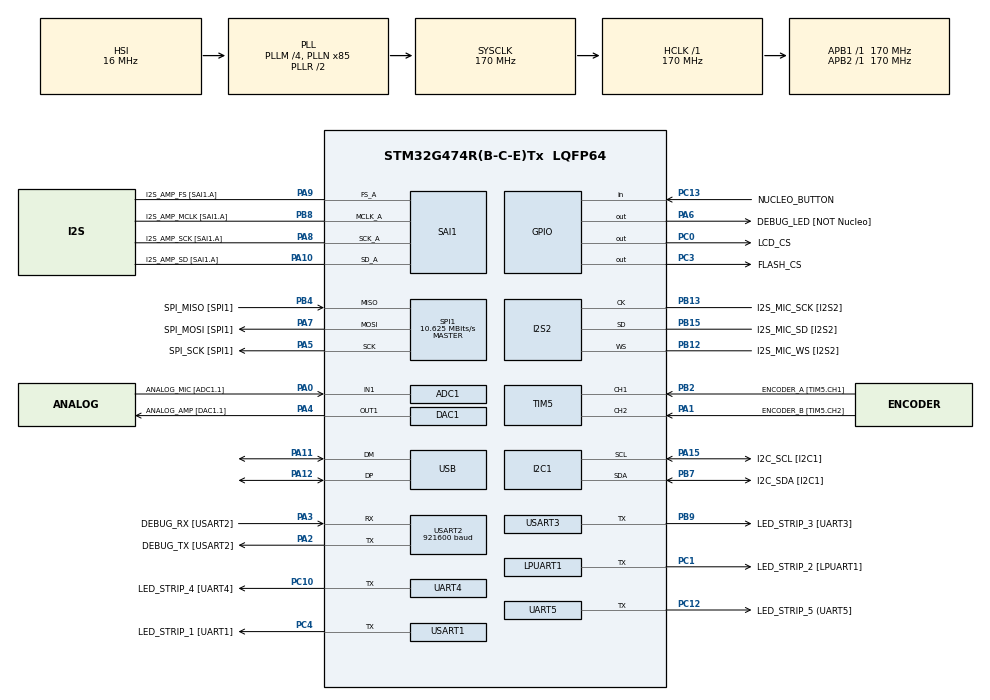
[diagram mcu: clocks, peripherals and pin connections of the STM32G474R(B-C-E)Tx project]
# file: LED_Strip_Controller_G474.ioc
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ADC1.Channel-0\#ChannelRegularConversion=ADC_CHANNEL_1
ADC1.NbrOfConversionFlag=1
ADC1.OffsetNumber-0\#ChannelRegularConversion=ADC_OFFSET_NONE
ADC1.Rank-0\#ChannelRegularConversion=1
ADC1.SamplingTime-0\#ChannelRegularConversion=ADC_SAMPLETIME_2CYCLES_5
ADC1.master=1
CRC.DefaultInitValueUse=DEFAULT_INIT_VALUE_DISABLE
CRC.DefaultPolynomialUse=DEFAULT_POLYNOMIAL_ENABLE
CRC.InitValue=0xFFFFFFFF
CRC.InputDataInversionMode=CRC_INPUTDATA_INVERSION_BYTE
CRC.OutputDataInversionMode=CRC_OUTPUTDATA_INVERSION_ENABLE
DAC1.DAC_Channel-DAC_OUT2_Int=DAC_CHANNEL_2
DAC3.DAC_Channel-DAC_OUT2_Int=DAC_CHANNEL_2
DAC4.DAC_Channel-DAC_OUT2_Int=DAC_CHANNEL_2
Dma.LPUART1_TX.2.Direction=DMA_MEMORY_TO_PERIPH
Dma.LPUART1_TX.2.EventEnable=DISABLE
Dma.LPUART1_TX.2.Instance=DMA1_Channel2
Dma.LPUART1_TX.2.MemDataAlignment=DMA_MDATAALIGN_BYTE
Dma.LPUART1_TX.2.MemInc=DMA_MINC_ENABLE
Dma.LPUART1_TX.2.Mode=DMA_NORMAL
Dma.LPUART1_TX.2.PeriphDataAlignment=DMA_PDATAALIGN_BYTE
Dma.LPUART1_TX.2.PeriphInc=DMA_PINC_DISABLE
Dma.LPUART1_TX.2.Polarity=HAL_DMAMUX_REQ_GEN_RISING
Dma.LPUART1_TX.2.Priority=DMA_PRIORITY_LOW
Dma.LPUART1_TX.2.RequestNumber=1
Dma.LPUART1_TX.2.SignalID=NONE
Dma.LPUART1_TX.2.SyncEnable=DISABLE
Dma.LPUART1_TX.2.SyncPolarity=HAL_DMAMUX_SYNC_NO_EVENT
Dma.LPUART1_TX.2.SyncRequestNumber=1
Dma.LPUART1_TX.2.SyncSignalID=NONE
Dma.Request0=USART1_TX
Dma.Request1=USART3_TX
Dma.Request2=LPUART1_TX
Dma.Request3=SPI1_TX
Dma.Request4=UART4_TX
Dma.Request5=UART5_TX
Dma.Request6=SPI2_RX
Dma.Request7=SAI1_A
Dma.Request8=SPI1_RX
Dma.SAI1_A.7.Direction=DMA_MEMORY_TO_PERIPH
Dma.SAI1_A.7.EventEnable=DISABLE
Dma.SAI1_A.7.Instance=DMA1_Channel7
Dma.SAI1_A.7.MemDataAlignment=DMA_MDATAALIGN_WORD
Dma.SAI1_A.7.MemInc=DMA_MINC_ENABLE
Dma.SAI1_A.7.Mode=DMA_CIRCULAR
Dma.SAI1_A.7.PeriphDataAlignment=DMA_PDATAALIGN_WORD
Dma.SAI1_A.7.PeriphInc=DMA_PINC_DISABLE
Dma.SAI1_A.7.Polarity=HAL_DMAMUX_REQ_GEN_RISING
Dma.SAI1_A.7.Priority=DMA_PRIORITY_LOW
Dma.SAI1_A.7.RequestNumber=1
Dma.SAI1_A.7.SignalID=NONE
Dma.SAI1_A.7.SyncEnable=DISABLE
Dma.SAI1_A.7.SyncPolarity=HAL_DMAMUX_SYNC_NO_EVENT
Dma.SAI1_A.7.SyncRequestNumber=1
Dma.SAI1_A.7.SyncSignalID=NONE
Dma.SPI1_RX.8.Direction=DMA_PERIPH_TO_MEMORY
Dma.SPI1_RX.8.EventEnable=DISABLE
Dma.SPI1_RX.8.Instance=DMA2_Channel1
Dma.SPI1_RX.8.MemDataAlignment=DMA_MDATAALIGN_BYTE
Dma.SPI1_RX.8.MemInc=DMA_MINC_ENABLE
Dma.SPI1_RX.8.Mode=DMA_NORMAL
Dma.SPI1_RX.8.PeriphDataAlignment=DMA_PDATAALIGN_BYTE
Dma.SPI1_RX.8.PeriphInc=DMA_PINC_DISABLE
Dma.SPI1_RX.8.Polarity=HAL_DMAMUX_REQ_GEN_RISING
Dma.SPI1_RX.8.Priority=DMA_PRIORITY_LOW
Dma.SPI1_RX.8.RequestNumber=1
Dma.SPI1_RX.8.SignalID=NONE
Dma.SPI1_RX.8.SyncEnable=DISABLE
Dma.SPI1_RX.8.SyncPolarity=HAL_DMAMUX_SYNC_NO_EVENT
Dma.SPI1_RX.8.SyncRequestNumber=1
Dma.SPI1_RX.8.SyncSignalID=NONE
Dma.SPI1_TX.3.Direction=DMA_MEMORY_TO_PERIPH
Dma.SPI1_TX.3.EventEnable=DISABLE
Dma.SPI1_TX.3.Instance=DMA1_Channel4
Dma.SPI1_TX.3.MemDataAlignment=DMA_MDATAALIGN_BYTE
Dma.SPI1_TX.3.MemInc=DMA_MINC_ENABLE
Dma.SPI1_TX.3.Mode=DMA_NORMAL
Dma.SPI1_TX.3.PeriphDataAlignment=DMA_PDATAALIGN_BYTE
Dma.SPI1_TX.3.PeriphInc=DMA_PINC_DISABLE
Dma.SPI1_TX.3.Polarity=HAL_DMAMUX_REQ_GEN_RISING
Dma.SPI1_TX.3.Priority=DMA_PRIORITY_LOW
Dma.SPI1_TX.3.RequestNumber=1
Dma.SPI1_TX.3.SignalID=NONE
Dma.SPI1_TX.3.SyncEnable=DISABLE
Dma.SPI1_TX.3.SyncPolarity=HAL_DMAMUX_SYNC_NO_EVENT
Dma.SPI1_TX.3.SyncRequestNumber=1
Dma.SPI1_TX.3.SyncSignalID=NONE
Dma.SPI2_RX.6.Direction=DMA_PERIPH_TO_MEMORY
Dma.SPI2_RX.6.EventEnable=DISABLE
Dma.SPI2_RX.6.Instance=DMA1_Channel8
Dma.SPI2_RX.6.MemDataAlignment=DMA_MDATAALIGN_HALFWORD
Dma.SPI2_RX.6.MemInc=DMA_MINC_ENABLE
Dma.SPI2_RX.6.Mode=DMA_CIRCULAR
Dma.SPI2_RX.6.PeriphDataAlignment=DMA_PDATAALIGN_HALFWORD
Dma.SPI2_RX.6.PeriphInc=DMA_PINC_DISABLE
Dma.SPI2_RX.6.Polarity=HAL_DMAMUX_REQ_GEN_RISING
Dma.SPI2_RX.6.Priority=DMA_PRIORITY_LOW
Dma.SPI2_RX.6.RequestNumber=1
Dma.SPI2_RX.6.SignalID=NONE
Dma.SPI2_RX.6.SyncEnable=DISABLE
Dma.SPI2_RX.6.SyncPolarity=HAL_DMAMUX_SYNC_NO_EVENT
Dma.SPI2_RX.6.SyncRequestNumber=1
Dma.SPI2_RX.6.SyncSignalID=NONE
Dma.UART4_TX.4.Direction=DMA_MEMORY_TO_PERIPH
Dma.UART4_TX.4.EventEnable=DISABLE
Dma.UART4_TX.4.Instance=DMA1_Channel5
Dma.UART4_TX.4.MemDataAlignment=DMA_MDATAALIGN_BYTE
Dma.UART4_TX.4.MemInc=DMA_MINC_ENABLE
Dma.UART4_TX.4.Mode=DMA_NORMAL
Dma.UART4_TX.4.PeriphDataAlignment=DMA_PDATAALIGN_BYTE
Dma.UART4_TX.4.PeriphInc=DMA_PINC_DISABLE
Dma.UART4_TX.4.Polarity=HAL_DMAMUX_REQ_GEN_RISING
Dma.UART4_TX.4.Priority=DMA_PRIORITY_LOW
Dma.UART4_TX.4.RequestNumber=1
Dma.UART4_TX.4.SignalID=NONE
Dma.UART4_TX.4.SyncEnable=DISABLE
Dma.UART4_TX.4.SyncPolarity=HAL_DMAMUX_SYNC_NO_EVENT
Dma.UART4_TX.4.SyncRequestNumber=1
Dma.UART4_TX.4.SyncSignalID=NONE
Dma.UART5_TX.5.Direction=DMA_MEMORY_TO_PERIPH
Dma.UART5_TX.5.EventEnable=DISABLE
Dma.UART5_TX.5.Instance=DMA1_Channel6
Dma.UART5_TX.5.MemDataAlignment=DMA_MDATAALIGN_BYTE
Dma.UART5_TX.5.MemInc=DMA_MINC_ENABLE
Dma.UART5_TX.5.Mode=DMA_NORMAL
Dma.UART5_TX.5.PeriphDataAlignment=DMA_PDATAALIGN_BYTE
Dma.UART5_TX.5.PeriphInc=DMA_PINC_DISABLE
Dma.UART5_TX.5.Polarity=HAL_DMAMUX_REQ_GEN_RISING
Dma.UART5_TX.5.Priority=DMA_PRIORITY_LOW
Dma.UART5_TX.5.RequestNumber=1
Dma.UART5_TX.5.SignalID=NONE
Dma.UART5_TX.5.SyncEnable=DISABLE
Dma.UART5_TX.5.SyncPolarity=HAL_DMAMUX_SYNC_NO_EVENT
Dma.UART5_TX.5.SyncRequestNumber=1
Dma.UART5_TX.5.SyncSignalID=NONE
Dma.USART1_TX.0.Direction=DMA_MEMORY_TO_PERIPH
Dma.USART1_TX.0.EventEnable=DISABLE
Dma.USART1_TX.0.Instance=DMA1_Channel1
Dma.USART1_TX.0.MemDataAlignment=DMA_MDATAALIGN_BYTE
Dma.USART1_TX.0.MemInc=DMA_MINC_ENABLE
Dma.USART1_TX.0.Mode=DMA_NORMAL
Dma.USART1_TX.0.PeriphDataAlignment=DMA_PDATAALIGN_BYTE
Dma.USART1_TX.0.PeriphInc=DMA_PINC_DISABLE
Dma.USART1_TX.0.Polarity=HAL_DMAMUX_REQ_GEN_RISING
Dma.USART1_TX.0.Priority=DMA_PRIORITY_LOW
Dma.USART1_TX.0.RequestNumber=1
Dma.USART1_TX.0.SignalID=NONE
Dma.USART1_TX.0.SyncEnable=DISABLE
Dma.USART1_TX.0.SyncPolarity=HAL_DMAMUX_SYNC_NO_EVENT
Dma.USART1_TX.0.SyncRequestNumber=1
Dma.USART1_TX.0.SyncSignalID=NONE
Dma.USART3_TX.1.Direction=DMA_MEMORY_TO_PERIPH
Dma.USART3_TX.1.EventEnable=DISABLE
Dma.USART3_TX.1.Instance=DMA1_Channel3
Dma.USART3_TX.1.MemDataAlignment=DMA_MDATAALIGN_BYTE
Dma.USART3_TX.1.MemInc=DMA_MINC_ENABLE
Dma.USART3_TX.1.Mode=DMA_NORMAL
Dma.USART3_TX.1.PeriphDataAlignment=DMA_PDATAALIGN_BYTE
Dma.USART3_TX.1.PeriphInc=DMA_PINC_DISABLE
Dma.USART3_TX.1.Polarity=HAL_DMAMUX_REQ_GEN_RISING
Dma.USART3_TX.1.Priority=DMA_PRIORITY_LOW
Dma.USART3_TX.1.RequestNumber=1
Dma.USART3_TX.1.SignalID=NONE
Dma.USART3_TX.1.SyncEnable=DISABLE
Dma.USART3_TX.1.SyncPolarity=HAL_DMAMUX_SYNC_NO_EVENT
Dma.USART3_TX.1.SyncRequestNumber=1
Dma.USART3_TX.1.SyncSignalID=NONE
I2C1.Timing=0x40B285C2
I2S2.AudioFreq=I2S_AUDIOFREQ_32K
I2S2.DataFormat=I2S_DATAFORMAT_24B
I2S2.ErrorAudioFreq=0.0 %
I2S2.FullDuplexMode=I2S_FULLDUPLEXMODE_DISABLE
I2S2.Instance=SPI$Index
I2S2.Mode=I2S_MODE_MASTER_RX
I2S2.RealAudioFreq=32.003 KHz
I2S2.VirtualMode=I2S_MODE_MASTER
LPUART1.BaudRate=2400000
LPUART1.FIFOMode=UART_FIFOMODE_DISABLE
LPUART1.Mode=UART_MODE_TX
LPUART1.OneBitSampling=UART_ONE_BIT_SAMPLE_ENABLE
LPUART1.TXFIFOThreshold=UART_TXFIFO_THRESHOLD_1_2
LPUART1.TxPinLevelInvertParam=UART_ADVFEATURE_TXINV_ENABLE
LPUART1.WordLength=UART_WORDLENGTH_7B
Mcu.Family=STM32G4
Mcu.Name=STM32G474R(B-C-E)Tx
Mcu.Package=LQFP64
Mcu.UserConstants=LED2_UART_H,$$_LPUART1_IP_HANDLE_$$;DEBUG_UART_H,$$_USART2_IP_HANDLE_$$;MIC_ADC_H,$$_ADC1_IP_HANDLE_$$;I2C1_H,$$_I2C1_IP_HANDLE_$$;AMP_DAC_H,$$_DAC1_IP_HANDLE_$$;LCD_SPI_H,$$_SPI1_IP_HANDLE_$$;PERIODIC_TIMER_H,$$_TIM16_IP_HANDLE_$$;LED4_UART_H,$$_UART4_IP_HANDLE_$$;DELAY_TIMER_H,$$_TIM17_IP_HANDLE_$$;LED5_UART_H,$$_UART5_IP_HANDLE_$$;LED1_UART_H,$$_USART1_IP_HANDLE_$$;LED3_UART_H,$$_USART3_IP_HANDLE_$$;I2S_AMP_H,$$_SAI1_IP_HANDLE_$$;I2S_MIC_H,$$_I2S2_IP_HANDLE_$$
NVIC.DMA1_Channel1_IRQn=true\:0\:0\:false\:false\:true\:false\:true\:true
NVIC.DMA1_Channel2_IRQn=true\:0\:0\:false\:false\:true\:false\:true\:true
NVIC.DMA1_Channel3_IRQn=true\:0\:0\:false\:false\:true\:false\:true\:true
NVIC.DMA1_Channel4_IRQn=true\:0\:0\:false\:false\:true\:false\:true\:true
NVIC.DMA1_Channel5_IRQn=true\:0\:0\:false\:false\:true\:false\:true\:true
NVIC.DMA1_Channel6_IRQn=true\:0\:0\:false\:false\:true\:false\:true\:true
NVIC.DMA1_Channel7_IRQn=true\:0\:0\:false\:false\:true\:false\:true\:true
NVIC.DMA1_Channel8_IRQn=true\:0\:0\:false\:false\:true\:false\:true\:true
NVIC.DMA2_Channel1_IRQn=true\:0\:0\:false\:false\:true\:false\:true\:true
NVIC.PriorityGroup=NVIC_PRIORITYGROUP_4
NVIC.TIM1_UP_TIM16_IRQn=true\:12\:0\:true\:false\:true\:true\:true\:true
PA0.GPIO_Label=ANALOG_MIC [ADC1.1]
PA0.Mode=IN1-Single-Ended
PA0.Signal=ADC1_IN1
PA1.GPIO_Label=ENCODER_B [TIM5.CH2]
PA1.Signal=S_TIM5_CH2
PA10.GPIO_Label=I2S_AMP_SD [SAI1.A]
PA10.GPIO_Speed=GPIO_SPEED_FREQ_LOW
PA10.Mode=SAI_A_MasterWithClock
PA10.Signal=SAI1_SD_A
PA11.Mode=Device
PA11.Signal=USB_DM
PA12.Mode=Device
PA12.Signal=USB_DP
PA13.GPIO_Label=SWDIO
PA13.Mode=Trace_Asynchronous_SW
PA13.Signal=SYS_JTMS-SWDIO
PA14.GPIO_Label=SWCLK
PA14.Mode=Trace_Asynchronous_SW
PA14.Signal=SYS_JTCK-SWCLK
PA15.GPIO_Label=I2C_SCL [I2C1]
PA15.Mode=I2C
PA15.Signal=I2C1_SCL
PA2.GPIO_Label=DEBUG_TX [USART2]
PA2.GPIO_Speed=GPIO_SPEED_FREQ_HIGH
PA2.Mode=Asynchronous
PA2.Signal=USART2_TX
PA3.GPIO_Label=DEBUG_RX [USART2]
PA3.Mode=Asynchronous
PA3.Signal=USART2_RX
PA4.GPIO_Label=ANALOG_AMP [DAC1.1]
PA4.Signal=COMP_DAC11_group
PA5.GPIO_Label=SPI_SCK [SPI1]
PA5.GPIO_Speed=GPIO_SPEED_FREQ_VERY_HIGH
PA5.Mode=Full_Duplex_Master
PA5.Signal=SPI1_SCK
PA6.GPIO_Label=DEBUG_LED [NOT Nucleo]
PA6.Signal=GPIO_Output
PA7.GPIO_Label=SPI_MOSI [SPI1]
PA7.GPIO_Speed=GPIO_SPEED_FREQ_VERY_HIGH
PA7.Mode=Full_Duplex_Master
PA7.Signal=SPI1_MOSI
PA8.GPIO_Label=I2S_AMP_SCK [SAI1.A]
PA8.Mode=SAI_A_MasterWithClock
PA8.Signal=SAI1_SCK_A
PA9.GPIO_Label=I2S_AMP_FS [SAI1.A]
PA9.Mode=SAI_A_MasterWithClock
PA9.Signal=SAI1_FS_A
PB12.GPIO_Label=I2S_MIC_WS [I2S2]
PB12.GPIO_Speed=GPIO_SPEED_FREQ_LOW
PB12.Mode=Half_Duplex_Master
PB12.Signal=I2S2_WS
PB13.GPIO_Label=I2S_MIC_SCK [I2S2]
PB13.GPIO_Speed=GPIO_SPEED_FREQ_LOW
PB13.Mode=Half_Duplex_Master
PB13.Signal=I2S2_CK
PB15.GPIO_Label=I2S_MIC_SD [I2S2]
PB15.GPIO_PuPd=GPIO_PULLDOWN
PB15.GPIO_Speed=GPIO_SPEED_FREQ_LOW
PB15.Mode=Half_Duplex_Master
PB15.Signal=I2S2_SD
PB2.GPIO_Label=ENCODER_A [TIM5.CH1]
PB2.Signal=S_TIM5_CH1
PB3.GPIO_Label=SWO
PB3.Mode=Trace_Asynchronous_SW
PB3.Signal=SYS_JTDO-SWO
PB4.GPIO_Label=SPI_MISO [SPI1]
PB4.Mode=Full_Duplex_Master
PB4.Signal=SPI1_MISO
PB7.GPIO_Label=I2C_SDA [I2C1]
PB7.Mode=I2C
PB7.Signal=I2C1_SDA
PB8-BOOT0.GPIO_Label=I2S_AMP_MCLK [SAI1.A]
PB8-BOOT0.Mode=SAI_A_MasterWithClock
PB8-BOOT0.Signal=SAI1_MCLK_A
PB9.GPIO_Label=LED_STRIP_3 [UART3]
PB9.GPIO_ModeDefaultOD=GPIO_MODE_AF_PP
PB9.GPIO_Speed=GPIO_SPEED_FREQ_HIGH
PB9.Mode=Half_duplex(single_wire_mode)
PB9.Signal=USART3_TX
PC0.GPIO_Label=LCD_CS
PC0.Signal=GPIO_Output
PC1.GPIO_Label=LED_STRIP_2 [LPUART1]
PC1.GPIO_Speed=GPIO_SPEED_FREQ_HIGH
PC1.Mode=Half_duplex(single_wire_mode)
PC1.Signal=LPUART1_TX
PC10.GPIO_Label=LED_STRIP_4 [UART4]
PC10.GPIO_ModeDefaultOD=GPIO_MODE_AF_PP
PC10.GPIO_Speed=GPIO_SPEED_FREQ_HIGH
PC10.Mode=Half_duplex(single_wire_mode)
PC10.Signal=UART4_TX
PC12.GPIO_Label=LED_STRIP_5 (UART5]
PC12.GPIO_ModeDefaultOD=GPIO_MODE_AF_PP
PC12.GPIO_Speed=GPIO_SPEED_FREQ_HIGH
PC12.Mode=Half_duplex(single_wire_mode)
PC12.Signal=UART5_TX
PC13.GPIO_Label=NUCLEO_BUTTON
PC13.Signal=GPIO_Input
PC14-OSC32_IN.GPIO_Label=RCC_OSC32_IN
PC14-OSC32_IN.Mode=LSE-External-Oscillator
PC14-OSC32_IN.Signal=RCC_OSC32_IN
PC15-OSC32_OUT.GPIO_Label=RCC_OSC32_OUT
PC15-OSC32_OUT.Mode=LSE-External-Oscillator
PC15-OSC32_OUT.Signal=RCC_OSC32_OUT
PC3.GPIO_Label=FLASH_CS
PC3.Signal=GPIO_Output
PC4.GPIO_Label=LED_STRIP_1 [UART1]
PC4.GPIO_ModeDefaultOD=GPIO_MODE_AF_PP
PC4.GPIO_Speed=GPIO_SPEED_FREQ_HIGH
PC4.Mode=Half_duplex(single_wire_mode)
PC4.Signal=USART1_TX
PF0-OSC_IN.GPIO_Label=RCC_OSC_IN
PF0-OSC_IN.Signal=RCC_OSC_IN
PF1-OSC_OUT.GPIO_Label=RCC_OSC_OUT
PF1-OSC_OUT.Signal=RCC_OSC_OUT
ProjectManager.HeapSize=0x2000
ProjectManager.StackSize=0x800
ProjectManager.TargetToolchain=STM32CubeIDE
RCC.ADC12Freq_Value=170000000
RCC.ADC345Freq_Value=170000000
RCC.AHBFreq_Value=170000000
RCC.APB1Freq_Value=170000000
RCC.APB1TimFreq_Value=170000000
RCC.APB2Freq_Value=170000000
RCC.APB2TimFreq_Value=170000000
RCC.CK48CLockSelection=RCC_USBCLKSOURCE_HSI48
RCC.CortexFreq_Value=170000000
RCC.EXTERNAL_CLOCK_VALUE=12288000
RCC.HCLKFreq_Value=170000000
RCC.HSE_VALUE=24000000
RCC.HSI48_VALUE=48000000
RCC.HSI_VALUE=16000000
RCC.PLLM=RCC_PLLM_DIV4
RCC.PLLN=85
RCC.RTCClockSelection=RCC_RTCCLKSOURCE_LSE
RCC.SYSCLKFreq_VALUE=170000000
RCC.SYSCLKSource=RCC_SYSCLKSOURCE_PLLCLK
RCC.USBFreq_Value=48000000
RCC.VCOOutputFreq_Value=340000000
RTC.Alarm-Alarm\ A=RTC_ALARM_A
RTC.Alarm_B-Alarm\ B=RTC_ALARM_B
SAI1.AudioFrequency-SAI_A_MasterWithClock=SAI_AUDIO_FREQUENCY_32K
SAI1.DataSize-SAI_A_MasterWithClock=SAI_DATASIZE_16
SAI1.FrameLength-SAI_A_MasterWithClock=32
SAI1.Instance-SAI_A_MasterWithClock=SAI$Index_Block_A
SAI1.MckOutput-SAI_A_MasterWithClock=SAI_MCK_OUTPUT_ENABLE
SAI1.MonoStereoMode-SAI_A_MasterWithClock=SAI_MONOMODE
SAI1.SlotActive-SAI_A_MasterWithClock=0x00000003
SAI1.VirtualMode-SAI_A_MasterWithClock=VM_MASTER
SH.COMP_DAC11_group.0=DAC1_OUT1,DAC_OUT1_ExtAndInt
SH.S_TIM5_CH1.0=TIM5_CH1,Encoder_Interface
SH.S_TIM5_CH2.0=TIM5_CH2,Encoder_Interface
SPI1.BaudRatePrescaler=SPI_BAUDRATEPRESCALER_16
SPI1.CalculateBaudRate=10.625 MBits/s
SPI1.DataSize=SPI_DATASIZE_8BIT
SPI1.Direction=SPI_DIRECTION_2LINES
SPI1.Mode=SPI_MODE_MASTER
SPI1.VirtualType=VM_MASTER
TIM16.PeriodNoDither=999
TIM16.Prescaler=169
TIM17.PeriodNoDither=999
TIM17.Prescaler=169
TIM6.PeriodNoDither=999
TIM6.Prescaler=169
TIM7.PeriodNoDither=999
TIM7.Prescaler=169
UART4.BaudRate=2400000
UART4.FIFOMode=FIFOMODE_DISABLE
UART4.Mode=MODE_TX
UART4.OneBitSampling=UART_ONE_BIT_SAMPLE_ENABLE
UART4.OverSampling=UART_OVERSAMPLING_8
UART4.TXFIFOThreshold=TXFIFO_THRESHOLD_HALFFULL
UART4.TxPinLevelInvertParam=UART_ADVFEATURE_TXINV_ENABLE
UART4.WordLength=WORDLENGTH_7B
UART5.BaudRate=2400000
UART5.FIFOMode=FIFOMODE_DISABLE
UART5.Mode=MODE_TX
UART5.OneBitSampling=UART_ONE_BIT_SAMPLE_ENABLE
UART5.OverSampling=UART_OVERSAMPLING_8
UART5.TXFIFOThreshold=TXFIFO_THRESHOLD_HALFFULL
UART5.TxPinLevelInvertParam=UART_ADVFEATURE_TXINV_ENABLE
UART5.WordLength=WORDLENGTH_7B
USART1.BaudRate=2400000
USART1.FIFOMode=FIFOMODE_DISABLE
USART1.Mode=MODE_TX
USART1.OneBitSampling=UART_ONE_BIT_SAMPLE_ENABLE
USART1.OverSampling=UART_OVERSAMPLING_8
USART1.TXFIFOThreshold=TXFIFO_THRESHOLD_HALFFULL
USART1.TxPinLevelInvertParam=ADVFEATURE_TXINV_ENABLE
USART1.VirtualMode-Half_duplex(single_wire_mode)=VM_ASYNC
USART1.WordLength=WORDLENGTH_7B
USART2.BaudRate=921600
USART2.FIFOMode=FIFOMODE_ENABLE
USART2.RXFIFOThreshold=RXFIFO_THRESHOLD_HALFFULL
USART2.TXFIFOThreshold=TXFIFO_THRESHOLD_HALFFULL
USART2.VirtualMode-Asynchronous=VM_ASYNC
USART3.BaudRate=2400000
USART3.Mode=MODE_TX
USART3.OneBitSampling=UART_ONE_BIT_SAMPLE_ENABLE
USART3.OverSampling=UART_OVERSAMPLING_8
USART3.TXFIFOThreshold=TXFIFO_THRESHOLD_HALFFULL
USART3.TxPinLevelInvertParam=ADVFEATURE_TXINV_ENABLE
USART3.VirtualMode-Half_duplex(single_wire_mode)=VM_ASYNC
USART3.WordLength=WORDLENGTH_7B
VP_CORDIC_VS_CORDIC.Mode=CORDIC_Activate
VP_CRC_VS_CRC.Mode=CRC_Activate
VP_DAC1_VS_DACI2.Mode=DAC_OUT2_Int
VP_DAC2_VS_DACI1.Mode=DAC_OUT1_Int
VP_DAC3_VS_DACI1.Mode=DAC_OUT1_Int
VP_DAC3_VS_DACI2.Mode=DAC_OUT2_Int
VP_DAC4_VS_DACI1.Mode=DAC_OUT1_Int
VP_DAC4_VS_DACI2.Mode=DAC_OUT2_Int
VP_FMAC_VS_FMAC.Mode=FMAC_Activate
VP_RTC_VS_RTC_Activate.Mode=RTC_Enabled
VP_RTC_VS_RTC_Alarm_A_Intern.Mode=Alarm A
VP_RTC_VS_RTC_Alarm_B_Intern.Mode=Alarm B
VP_RTC_VS_RTC_Calendar.Mode=RTC_Calendar
VP_SYS_VS_DBSignals.Mode=DisableDeadBatterySignals
VP_TIM16_VS_ClockSourceINT.Mode=Enable_Timer
VP_TIM17_VS_ClockSourceINT.Mode=Enable_Timer
VP_TIM6_VS_ClockSourceINT.Mode=Enable_Timer
VP_TIM7_VS_ClockSourceINT.Mode=Enable_Timer
board=NUCLEO-G474RE

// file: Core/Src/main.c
/* USER CODE BEGIN Header */
/**
  ******************************************************************************
  * @file           : main.c
  * @brief          : Main program body
  ******************************************************************************
  * @attention
  *
  * Copyright (c) 2026 STMicroelectronics.
  * All rights reserved.
  *
  * This software is licensed under terms that can be found in the LICENSE file
  * in the root directory of this software component.
  * If no LICENSE file comes with this software, it is provided AS-IS.
  *
  ******************************************************************************
  */
/* USER CODE END Header */
#include "main.h"
#include "adc.h"
#include "cordic.h"
#include "crc.h"
#include "dac.h"
#include "dma.h"
#include "fmac.h"
#include "i2c.h"
#include "i2s.h"
#include "usart.h"
#include "rtc.h"
#include "sai.h"
#include "spi.h"
#include "tim.h"
#include "usb.h"
#include "gpio.h"

/* USER CODE BEGIN Includes */

#include "app_global.h"

/* USER CODE END Includes */

void SystemClock_Config(void);

int main(void)
{

  /* MCU Configuration--------------------------------------------------------*/

  /* Reset of all peripherals, Initializes the Flash interface and the Systick. */
  HAL_Init();

  /* Configure the system clock */
  SystemClock_Config();

  /* Initialize all configured peripherals */
  MX_GPIO_Init();
  MX_DMA_Init();
  MX_RTC_Init();
  MX_CORDIC_Init();
  MX_FMAC_Init();
  MX_USART2_UART_Init();
  MX_LPUART1_UART_Init();
  MX_USART1_UART_Init();
  MX_USART3_UART_Init();
  MX_UART4_Init();
  MX_UART5_Init();
  MX_I2C1_Init();
  MX_SPI1_Init();
  MX_I2S2_Init();
  MX_SAI1_Init();
  MX_ADC1_Init();
  MX_DAC1_Init();
  MX_DAC2_Init();
  MX_DAC3_Init();
  MX_DAC4_Init();
  MX_TIM6_Init();
  MX_TIM7_Init();
  MX_TIM17_Init();
  MX_TIM16_Init();
  MX_USB_PCD_Init();
  MX_CRC_Init();
  MX_TIM5_Init();
  /* USER CODE BEGIN 2 */

  // Disable I/O buffering for STDxxx streams, so that I/O data is
  // sent/received immediately; no internal wait-for-EOL buffering
  setvbuf(stdout, NULL, _IONBF, 0);
  setvbuf(stdin, NULL, _IONBF, 0);
  setvbuf(stderr, NULL, _IONBF, 0);

  /* USER CODE END 2 */

  /* Infinite loop */

    /* USER CODE BEGIN 3 */
  v_app_main();
  /* USER CODE END 3 */
}

void SystemClock_Config(void)
{
  RCC_OscInitTypeDef RCC_OscInitStruct = {0};
  RCC_ClkInitTypeDef RCC_ClkInitStruct = {0};

  /** Configure the main internal regulator output voltage
  */
  HAL_PWREx_ControlVoltageScaling(PWR_REGULATOR_VOLTAGE_SCALE1_BOOST);

  /** Configure LSE Drive Capability
  */
  HAL_PWR_EnableBkUpAccess();
  __HAL_RCC_LSEDRIVE_CONFIG(RCC_LSEDRIVE_LOW);

  /** Initializes the RCC Oscillators according to the specified parameters
  * in the RCC_OscInitTypeDef structure.
  */
  RCC_OscInitStruct.OscillatorType = RCC_OSCILLATORTYPE_HSI|RCC_OSCILLATORTYPE_HSI48
                              |RCC_OSCILLATORTYPE_LSE;
  RCC_OscInitStruct.LSEState = RCC_LSE_ON;
  RCC_OscInitStruct.HSIState = RCC_HSI_ON;
  RCC_OscInitStruct.HSICalibrationValue = RCC_HSICALIBRATION_DEFAULT;
  RCC_OscInitStruct.HSI48State = RCC_HSI48_ON;
  RCC_OscInitStruct.PLL.PLLState = RCC_PLL_ON;
  RCC_OscInitStruct.PLL.PLLSource = RCC_PLLSOURCE_HSI;
  RCC_OscInitStruct.PLL.PLLM = RCC_PLLM_DIV4;
  RCC_OscInitStruct.PLL.PLLN = 85;
  RCC_OscInitStruct.PLL.PLLP = RCC_PLLP_DIV2;
  RCC_OscInitStruct.PLL.PLLQ = RCC_PLLQ_DIV2;
  RCC_OscInitStruct.PLL.PLLR = RCC_PLLR_DIV2;
  if (HAL_RCC_OscConfig(&RCC_OscInitStruct) != HAL_OK)
  {
    Error_Handler();
  }

  /** Initializes the CPU, AHB and APB buses clocks
  */
  RCC_ClkInitStruct.ClockType = RCC_CLOCKTYPE_HCLK|RCC_CLOCKTYPE_SYSCLK
                              |RCC_CLOCKTYPE_PCLK1|RCC_CLOCKTYPE_PCLK2;
  RCC_ClkInitStruct.SYSCLKSource = RCC_SYSCLKSOURCE_PLLCLK;
  RCC_ClkInitStruct.AHBCLKDivider = RCC_SYSCLK_DIV1;
  RCC_ClkInitStruct.APB1CLKDivider = RCC_HCLK_DIV1;
  RCC_ClkInitStruct.APB2CLKDivider = RCC_HCLK_DIV1;

  if (HAL_RCC_ClockConfig(&RCC_ClkInitStruct, FLASH_LATENCY_4) != HAL_OK)
  {
    Error_Handler();
  }
}

void Error_Handler(void)
{
  __disable_irq();
  while (1)
  {
  }
}
